# TC37X register map
File version: 1.0.0
CPU: CM4 r0p1, little endian, MPU, FPU, VTOR, 3 interrupt priority bits
Registers are 16-bit, read-write, reset 0x0 unless marked. A register's access mark holds for its fields unless they carry their own. Offsets are from the block's base; [hi:lo] are bit positions; {n}, {i} and the like mark numbered series; 'fields as' and 'values as' point back to an identical list.

## DMU — ce_dmu
Base 0xF8040000
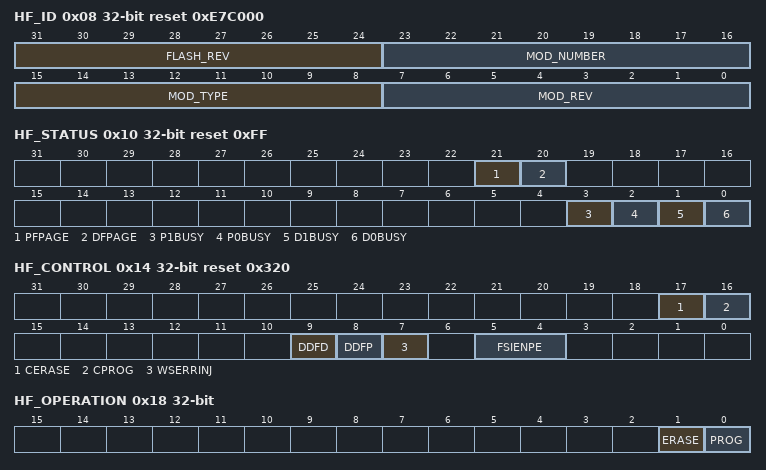
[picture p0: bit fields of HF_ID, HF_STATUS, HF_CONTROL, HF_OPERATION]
0x08 HF_ID 32-bit ro reset 0xE7C000 (reset mask 0xFFFF00) — Module Identification Register
  [31:24] FLASH_REV — Flash Revision - FLASH_REV
  [23:16] MOD_NUMBER — Module Number Value - MOD_NUMBER
  [15:8] MOD_TYPE — Module Type - MOD_TYPE
  [7:0] MOD_REV — Module Revision Number - MOD_REV
0x10 HF_STATUS 32-bit ro reset 0xFF — Flash Status Register
  [21] PFPAGE — Program Flash in Page Mode - PFPAGE
  [20] DFPAGE — Data Flash in Page Mode - DFPAGE
  [3] P1BUSY — Program Flash PF1BUSY - P1BUSY
  [2] P0BUSY — Program Flash PF0BUSY - P0BUSY
  [1] D1BUSY — Data Flash Bank 1 Busy - D1BUSY
  [0] D0BUSY — Data Flash Bank 0 Busy - D0BUSY
0x14 HF_CONTROL 32-bit reset 0x320 — Flash Control Register
  [17] CERASE wo — Clear Erase State - CERASE
  [16] CPROG wo — Clear Programming State - CPROG
  [9] DDFD — Disable Data Fetch from DF0_EEPROM - DDFD
  [8] DDFP — Disable Read from PFLASH - DDFP
  [7] WSERRINJ — PFlash Wait State ECC error injection - WSERRINJ
  [5:4] FSIENPE — Enable Program/Erase - FSIENPE
0x18 HF_OPERATION 32-bit ro — Flash Operation Register
  [1] ERASE — Erase State - ERASE
  [0] PROG — Programming State - PROG
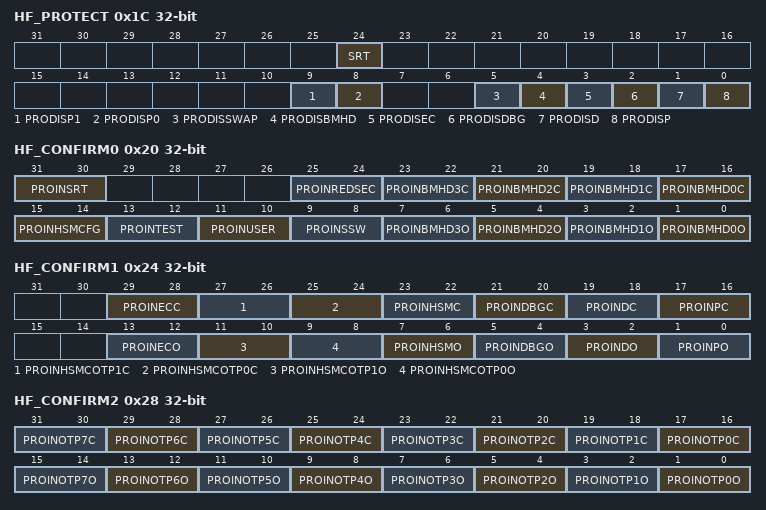
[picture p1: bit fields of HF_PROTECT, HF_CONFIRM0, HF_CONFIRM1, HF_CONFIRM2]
0x1C HF_PROTECT 32-bit ro — Flash Protection Status Register
  [24] SRT — Secure Retest Password Protection Disabled - SRT
  [9] PRODISP1 — Program Flash Protection Disable PRODISP1
  [8] PRODISP0 — Program Flash Protection Disable PRODISP0
  [5] PRODISSWAP — UCB_SWAP protection Disabled - PRODISSWAP
  [4] PRODISBMHD — BMHD Protection Disabled - PRODISBMHD
  [3] PRODISEC — Erase Counter Priority Protection Disabled - PRODISEC
  [2] PRODISDBG — Debug Interface Password Protection Disabled - PRODISDBG
  [1] PRODISD — DFLASH Protection Disabled - PRODISD
  [0] PRODISP — PFLASH Protection Disabled - PRODISP
0x20 HF_CONFIRM0 32-bit ro — Flash Confirm Status Register 0
  [31:30] PROINSRT — UCB_RETEST Confirmation - PROINSRT
  [25:24] PROINREDSEC — UCB_REDSEC Confirmation - PROINREDSEC
  [2n+17:2n+16] PROINBMHD{n}C (n=0..3) — UCB_BMHD{n}_COPY Confirmation - PROINBMHD{n}C
  [15:14] PROINHSMCFG — UCB_HSMCFG Confirmation - PROINHSMCFG
  [13:12] PROINTEST — UCB_TEST Confirmation - PROINTEST
  [11:10] PROINUSER — UCB_USER Confirmation - PROINUSER
  [9:8] PROINSSW — UCB_SSW Confirmation - PROINSSW
  [2n+1:2n] PROINBMHD{n}O (n=0..3) — UCB_BMHD{n}_ORIG Confirmation - PROINBMHD{n}O
0x24 HF_CONFIRM1 32-bit ro — Flash Confirm Status Register 1
  [29:28] PROINECC — UCB_ECPRIO_COPY Confirmation - PROINECC
  [27:26] PROINHSMCOTP1C — UCB_HSMCOTP1_COPY Protection - PROINHSMCOTP1C
  [25:24] PROINHSMCOTP0C — UCB_HSMCOTP0_COPY Protection - PROINHSMCOTP0C
  [23:22] PROINHSMC — UCB_HSM_COPY Confirmation - PROINHSMC
  [21:20] PROINDBGC — UCB_DBG_COPY Interface Confirmation - PROINDBGC
  [19:18] PROINDC — UCB_DFLASH_COPY Confirmation - PROINDC
  [17:16] PROINPC — UCB_PFLASH_COPY Confirmation - PROINPC
  [13:12] PROINECO — UCB_ECPRIO_ORIG Confirmation - PROINECO
  [11:10] PROINHSMCOTP1O — UCB_HSMCOTP1_ORIG Protection - PROINHSMCOTP1O
  [9:8] PROINHSMCOTP0O — UCB_HSMCOTP0_ORIG Protection - PROINHSMCOTP0O
  [7:6] PROINHSMO — UCB_HSM_ORIG Confirmation - PROINHSMO
  [5:4] PROINDBGO — UCB_DBG_ORIG Confirmation - PROINDBGO
  [3:2] PROINDO — UCB_DFLASH_ORIG Confirmation - PROINDO
  [1:0] PROINPO — UCB_PFLASH_ORIG Confirmation - PROINPO
0x28 HF_CONFIRM2 32-bit ro — Flash Confirm Status Register 2
  [2n+17:2n+16] PROINOTP{n}C (n=0..7) — UCB_OTP{n}_COPY Confirmation - PROINOTP{n}C
  [2n+1:2n] PROINOTP{n}O (n=0..7) — UCB_OTP{n}_ORIG Confirmation - PROINOTP{n}O
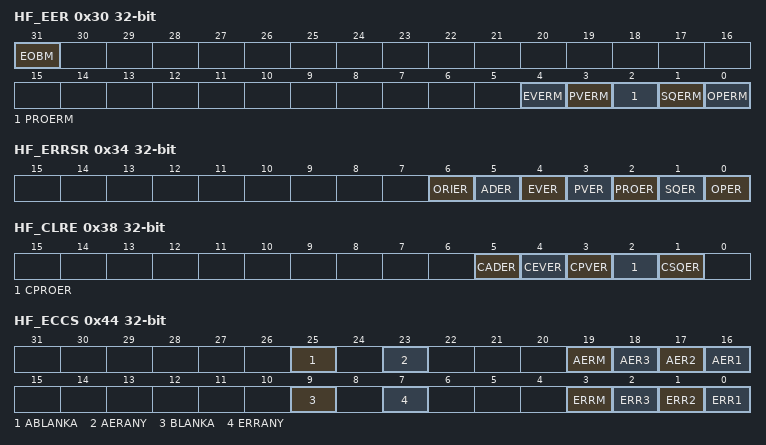
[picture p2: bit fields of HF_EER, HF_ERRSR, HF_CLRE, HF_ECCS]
0x30 HF_EER 32-bit — Enable Error Interrupt Control Register
  [31] EOBM — End of Busy Interrupt Mask - EOBM
  [4] EVERM — Erase Verify Error Interrupt Mask - EVERM
  [3] PVERM — Program Verify Error Interrupt Mask - PVERM
  [2] PROERM — Protection Error Interrupt Mask - PROERM
  [1] SQERM — Command Sequence Error Interrupt Mask - SQERM
  [0] OPERM — Operation Error Interrupt Mask - OPERM
0x34 HF_ERRSR 32-bit ro — Error Status Register
  [6] ORIER — Original Error - ORIER
  [5] ADER — SRI Bus Address ECC Error - ADER
  [4] EVER — Erase Verify Error - EVER
  [3] PVER — Program Verify Error - PVER
  [2] PROER — Protection Error - PROER
  [1] SQER — Command Sequence Error - SQER
  [0] OPER — Flash Operation Error - OPER
0x38 HF_CLRE 32-bit — Clear Error Register
  [5] CADER wo — Clear SRI Bus Address ECC Error - CADER
  [4] CEVER wo — Clear Erase Verify Error - CEVER
  [3] CPVER wo — Clear Program Verify Error - CPVER
  [2] CPROER wo — Clear Protection Error - CPROER
  [1] CSQER wo — Clear Command Sequence Error - CSQER
0x40 HF_ECCR 32-bit ro — DF0 ECC Read Register
  [21:0] RCODE — Error Correction Read Code - RCODE
0x44 HF_ECCS 32-bit ro — DF0 ECC Status Register
  [25] ABLANKA — Accumulated Blank Analog - ABLANKA
  [23] AERANY — Accumulated Any Read Access ECC Error - AERANY
  [19] AERM — Accumulated Multi-bit ECC Errors - AERM
  [18] AER3 — Accumulated Triple Bit ECC Errors - AER3
  [17] AER2 — Accumulated Double Bit ECC Errors - AER2
  [16] AER1 — Accumulated Single Bit ECC Errors - AER1
  [9] BLANKA — Read Access Blank Analog - BLANKA
  [7] ERRANY — Any Read Access ECC Error - ERRANY
  [3] ERRM — Read Access Multi-bit ECC Error - ERRM
  [2] ERR3 — Read Access Triple Bit ECC Error - ERR3
  [1] ERR2 — Read Access Double Bit ECC Error - ERR2
  [0] ERR1 — Read Access Single Bit ECC Error - ERR1
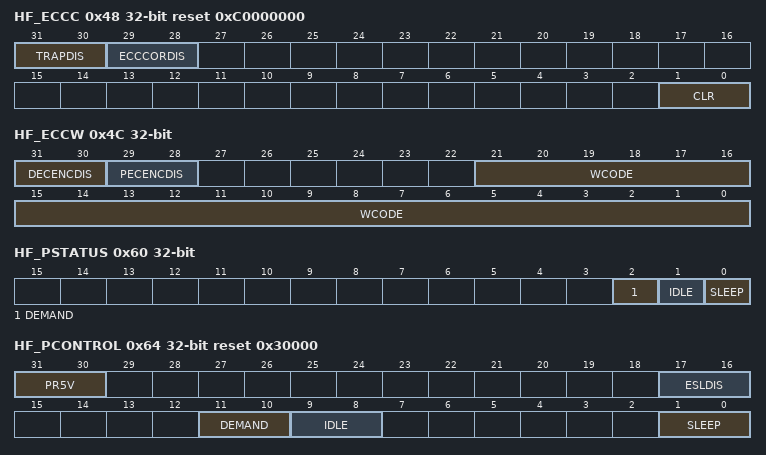
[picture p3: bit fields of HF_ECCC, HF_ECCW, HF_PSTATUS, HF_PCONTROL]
0x48 HF_ECCC 32-bit reset 0xC0000000 — DF0 ECC Control Register
  [31:30] TRAPDIS — Host Command Interface Uncorrectable ECC Bit Error Trap Disable - TRAPDIS
  [29:28] ECCCORDIS — Host Command Interface ECC Correction Disable - ECCCORDIS
  [1:0] CLR wo — Clear ECC status bits - CLR
0x4C HF_ECCW 32-bit — DF0 ECC Write Register
  [31:30] DECENCDIS — DFLASH ECC Encoding Disable - DECENCDIS
  [29:28] PECENCDIS — PFLASH ECC Encoding Disable - PECENCDIS
  [21:0] WCODE — Error Correction Write Code - WCODE
0x50 HF_CCONTROL 32-bit — Cranking Control Register
  [1:0] CRANKING — Cranking Mode Control - CRANKING
0x60 HF_PSTATUS 32-bit ro — Power Status Register
  [2] DEMAND — Demand - DEMAND
  [1] IDLE — Dynamic Idle - IDLE
  [0] SLEEP — Sleep Mode - SLEEP
0x64 HF_PCONTROL 32-bit reset 0x30000 — Power Control Register
  [31:30] PR5V — Programming Supply 5V - PR5V
  [17:16] ESLDIS — External Sleep Mode Request Disable - ESLDIS
  [11:10] DEMAND wo — Demand Enable - DEMAND
  [9:8] IDLE wo — Dynamic Idle Enable - IDLE
  [1:0] SLEEP — Sleep Mode Control - SLEEP
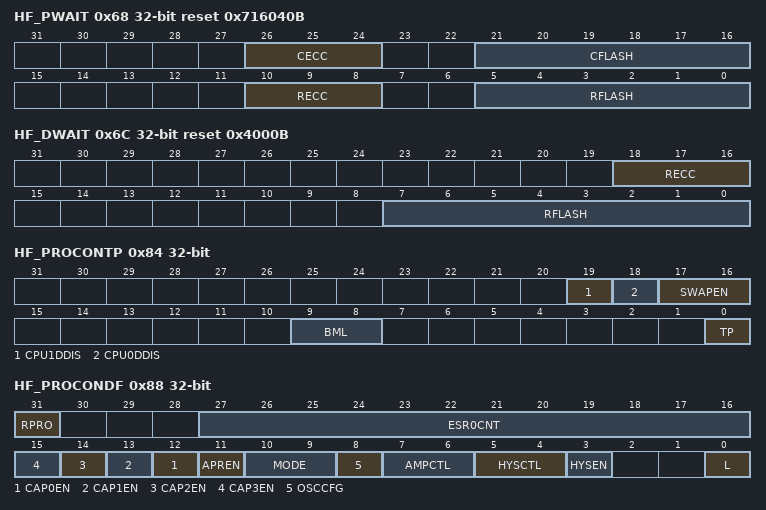
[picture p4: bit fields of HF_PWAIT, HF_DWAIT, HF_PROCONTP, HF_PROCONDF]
0x68 HF_PWAIT 32-bit reset 0x716040B — PFLASH Wait Cycle Register
  [26:24] CECC — Cranking Mode - CECC
  [21:16] CFLASH — Cranking Mode - CFLASH
  [10:8] RECC — Operation Mode - RECC
  [5:0] RFLASH — Operation Mode - RFLASH
0x6C HF_DWAIT 32-bit reset 0x4000B — DFLASH Wait Cycle Register
  [18:16] RECC — Operation Mode - RECC
  [7:0] RFLASH — Operation Mode - RFLASH
0x74 HF_PROCONUSR 32-bit ro — DF0 User Mode Control
  [1:0] MODE — DF0 User Mode Control - MODE
0x80 HF_PROCONPF 32-bit ro — PFLASH Protection Configuration
  [31] RPRO — Read Protection Configuration - RPRO
0x84 HF_PROCONTP 32-bit ro — Tuning Protection Configuration
  [19] CPU1DDIS — Disable direct LPB access
  [18] CPU0DDIS — Disable direct LPB access
  [17:16] SWAPEN — Enable SOTA mode - SWAPEN
  [9:8] BML — Boot Mode Lock - BML
  [0] TP — Tuning Protection - TP
0x88 HF_PROCONDF 32-bit ro — DFLASH Protection Configuration
  [31] RPRO — Read Protection Configuration - RPRO
  [27:16] ESR0CNT — ESR0 Prolongation Counter - ESR0CNT
  [n+12] CAP{n}EN (n=0..3) — OSC Capacitance {n} Enable (x=0-3) - CAP{n}EN
  [11] APREN — OSC Amplitude Regulation Enable - APREN
  [10:9] MODE — OSC Mode - MODE
  [8] OSCCFG — OSC Configuration by SSW - OSCCFG
  [7:6] AMPCTL — Amplitude Control
  [5:4] HYSCTL — Hysteresis Control
  [3] HYSEN — Hysteresis enable
  [0] L — DF0_EEPROM Locked for Write Protection - L
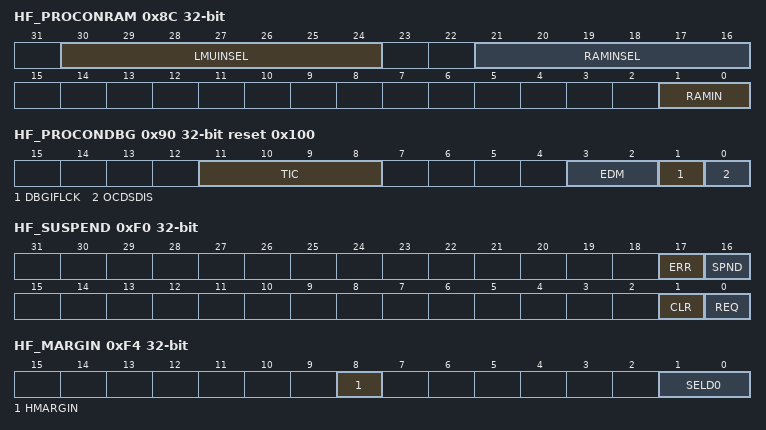
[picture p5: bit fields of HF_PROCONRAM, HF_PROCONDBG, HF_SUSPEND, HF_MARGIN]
0x8C HF_PROCONRAM 32-bit ro — RAM Configuration
  [30:24] LMUINSEL — LMU Initialization Selection - LMUINSEL
  [21:16] RAMINSEL — RAM Initialization Selection - RAMINSEL
  [1:0] RAMIN — RAM Initialization by SSW Control - RAMIN
0x90 HF_PROCONDBG 32-bit ro reset 0x100 — Debug Interface Protection Configuration
  [11:8] TIC — Tool Interface Control - TIC
  [3:2] EDM — Entered Debug Mode - EDM
  [1] DBGIFLCK — Debug Interface Locked - DBGIFLCK
  [0] OCDSDIS — OCDS Disabled - OCDSDIS
0xF0 HF_SUSPEND 32-bit — Suspend Control Register
  [17] ERR ro — Suspend Error - ERR
  [16] SPND ro — Flash Operation Suspended - SPND
  [1] CLR wo — Suspend Clear - CLR
  [0] REQ — Suspend Request - REQ
0xF4 HF_MARGIN 32-bit — Margin Control Register
  [8] HMARGIN — Hard Margin Selection - HMARGIN
  [1:0] SELD0 — DF0 Margin Read Selection - SELD0
0xF8 HF_ACCEN1 32-bit ro — Access Enable Register 1
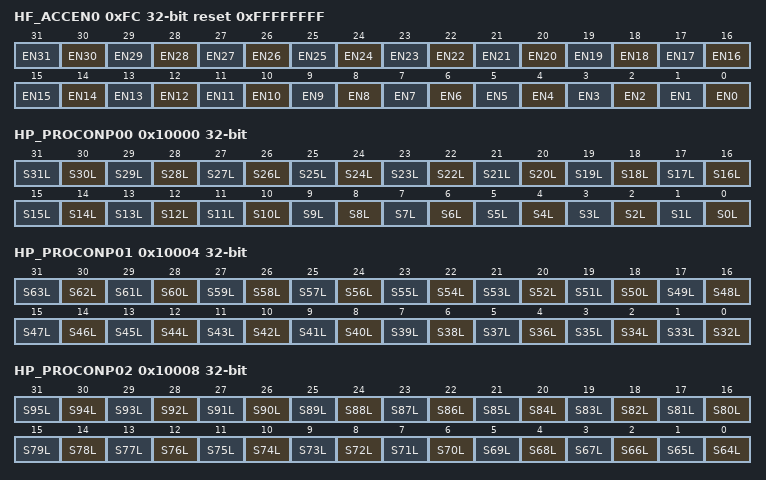
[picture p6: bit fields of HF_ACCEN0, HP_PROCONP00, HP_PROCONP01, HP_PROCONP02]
0xFC HF_ACCEN0 32-bit reset 0xFFFFFFFF — Access Enable Register 0
  [n] EN{n} (n=0..31) — Access Enable for Master TAG ID {n} - EN{n}
0x10000 HP_PROCONP00 32-bit ro — PFLASH Bank 0 Protection Configuration 0
  [n] S{n}L (n=0..31) — PFLASH p Sector {n} Locked for Write Protection - S{n}L
0x10004 HP_PROCONP01 32-bit ro — PFLASH Bank 0 Protection Configuration 1
  [n-32] S{n}L (n=32..63) — PFLASH p Sector {n} Locked for Write Protection - S{n}L
0x10008 HP_PROCONP02 32-bit ro — PFLASH Bank 0 Protection Configuration 2
  [n-64] S{n}L (n=64..95) — PFLASH p Sector {n} Locked for Write Protection - S{n}L
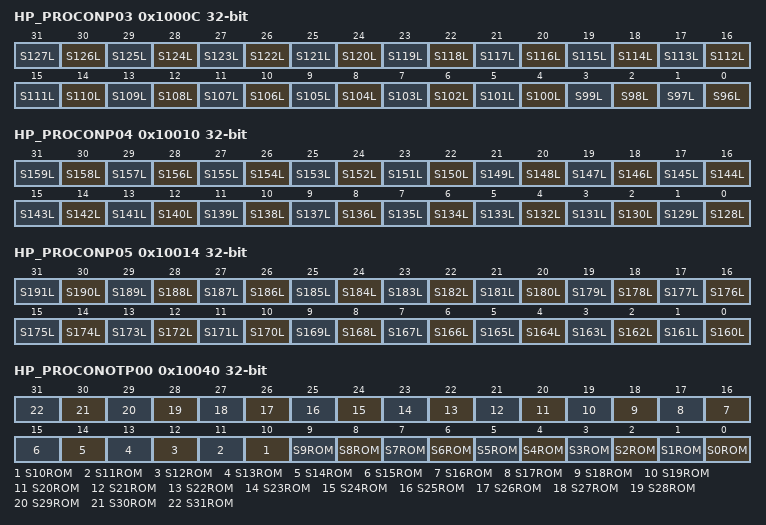
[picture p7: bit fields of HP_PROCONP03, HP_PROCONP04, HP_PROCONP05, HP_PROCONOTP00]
0x1000C HP_PROCONP03 32-bit ro — PFLASH Bank 0 Protection Configuration 3
  [n-96] S{n}L (n=96..127) — PFLASH p Sector {n} Locked for Write Protection - S{n}L
0x10010 HP_PROCONP04 32-bit ro — PFLASH Bank 0 Protection Configuration 4
  [n-128] S{n}L (n=128..159) — PFLASH p Sector {n} Locked for Write Protection - S{n}L
0x10014 HP_PROCONP05 32-bit ro — PFLASH Bank 0 Protection Configuration 5
  [n-160] S{n}L (n=160..191) — PFLASH p Sector {n} Locked for Write Protection - S{n}L
0x10040 HP_PROCONOTP00 32-bit ro — PFLASH Bank 0 OTP Protection Configuration 0
  [n] S{n}ROM (n=0..31) — PFLASH p Sector {n} Locked for Forever - S{n}ROM
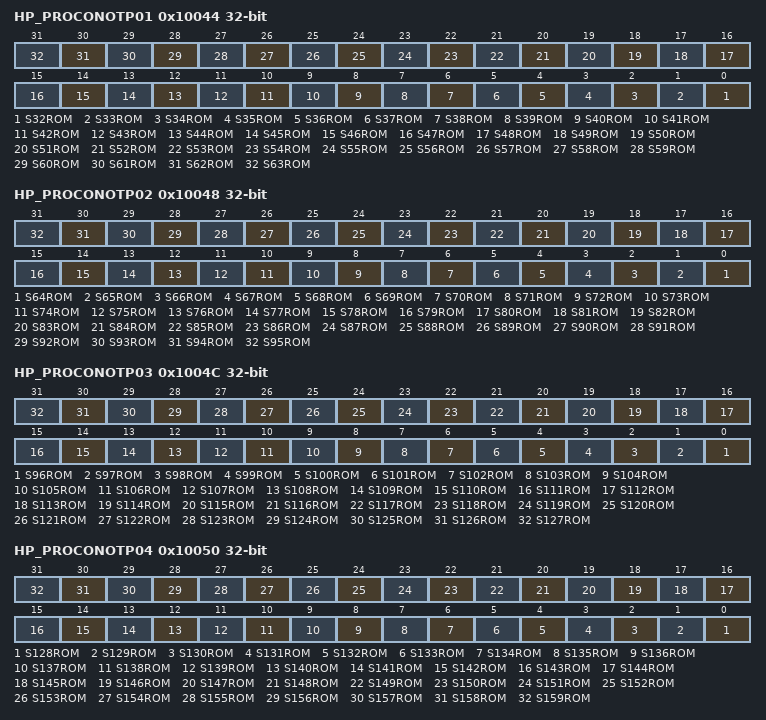
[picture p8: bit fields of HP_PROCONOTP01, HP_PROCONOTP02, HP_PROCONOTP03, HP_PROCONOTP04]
0x10044 HP_PROCONOTP01 32-bit ro — PFLASH Bank 0 OTP Protection Configuration 1
  [n-32] S{n}ROM (n=32..63) — PFLASH p Sector {n} Locked for Forever - S{n}ROM
0x10048 HP_PROCONOTP02 32-bit ro — PFLASH Bank 0 OTP Protection Configuration 2
  [n-64] S{n}ROM (n=64..95) — PFLASH p Sector {n} Locked for Forever - S{n}ROM
0x1004C HP_PROCONOTP03 32-bit ro — PFLASH Bank 0 OTP Protection Configuration 3
  [n-96] S{n}ROM (n=96..127) — PFLASH p Sector {n} Locked for Forever - S{n}ROM
0x10050 HP_PROCONOTP04 32-bit ro — PFLASH Bank 0 OTP Protection Configuration 4
  [n-128] S{n}ROM (n=128..159) — PFLASH p Sector {n} Locked for Forever - S{n}ROM
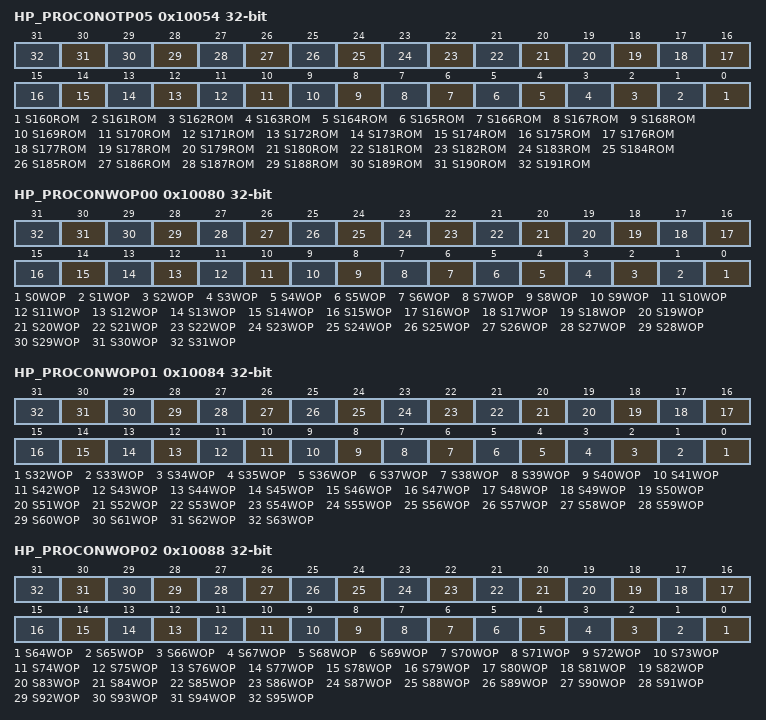
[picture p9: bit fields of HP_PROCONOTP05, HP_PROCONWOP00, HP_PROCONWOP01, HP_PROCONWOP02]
0x10054 HP_PROCONOTP05 32-bit ro — PFLASH Bank 0 OTP Protection Configuration 5
  [n-160] S{n}ROM (n=160..191) — PFLASH p Sector {n} Locked for Forever - S{n}ROM
0x10080 HP_PROCONWOP00 32-bit ro — PFLASH Bank 0 WOP Configuration 0
  [n] S{n}WOP (n=0..31) — PFLASH p Sector {n} Configured for Write-Once Protection - S{n}WOP
0x10084 HP_PROCONWOP01 32-bit ro — PFLASH Bank 0 WOP Configuration 1
  [n-32] S{n}WOP (n=32..63) — PFLASH p Sector {n} Configured for Write-Once Protection - S{n}WOP
0x10088 HP_PROCONWOP02 32-bit ro — PFLASH Bank 0 WOP Configuration 2
  [n-64] S{n}WOP (n=64..95) — PFLASH p Sector {n} Configured for Write-Once Protection - S{n}WOP
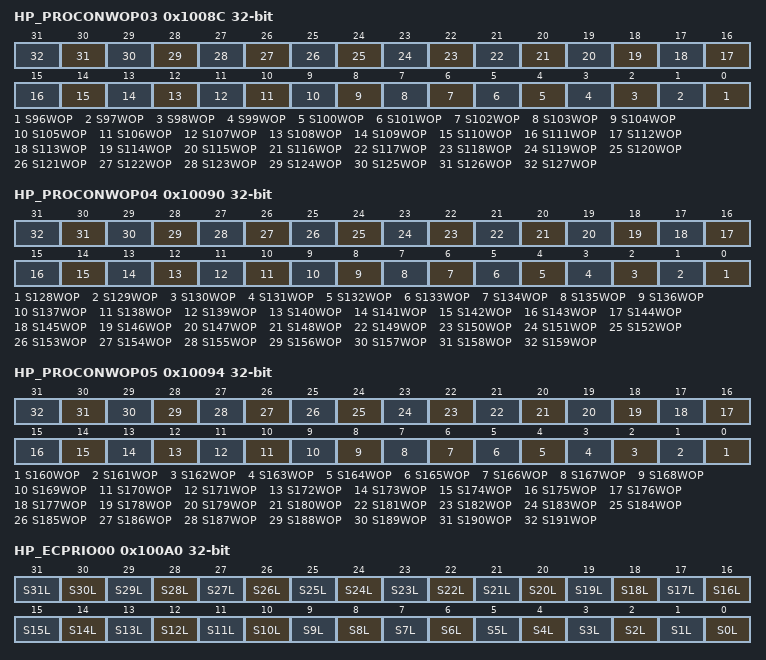
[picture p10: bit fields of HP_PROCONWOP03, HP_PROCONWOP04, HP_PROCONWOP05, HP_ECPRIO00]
0x1008C HP_PROCONWOP03 32-bit ro — PFLASH Bank 0 WOP Configuration 3
  [n-96] S{n}WOP (n=96..127) — PFLASH p Sector {n} Configured for Write-Once Protection - S{n}WOP
0x10090 HP_PROCONWOP04 32-bit ro — PFLASH Bank 0 WOP Configuration 4
  [n-128] S{n}WOP (n=128..159) — PFLASH p Sector {n} Configured for Write-Once Protection - S{n}WOP
0x10094 HP_PROCONWOP05 32-bit ro — PFLASH Bank 0 WOP Configuration 5
  [n-160] S{n}WOP (n=160..191) — PFLASH p Sector {n} Configured for Write-Once Protection - S{n}WOP
0x100A0 HP_ECPRIO00 32-bit ro — PFLASH Bank 0 Erase Counter Priority configuration 0
  [n] S{n}L (n=0..31) — PFLASH p Sector {n} Erase Counter priority - S{n}L
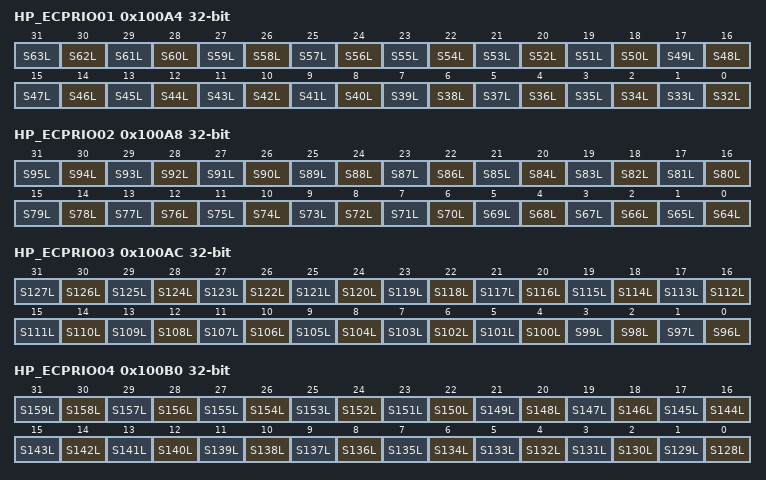
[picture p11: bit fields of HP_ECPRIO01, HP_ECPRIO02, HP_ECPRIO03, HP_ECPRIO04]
0x100A4 HP_ECPRIO01 32-bit ro — PFLASH Bank 0 Erase Counter Priority Configuration 1
  [n-32] S{n}L (n=32..63) — PFLASH p Sector {n} Erase Counter priority - S{n}L
0x100A8 HP_ECPRIO02 32-bit ro — PFLASH Bank 0 Erase Counter Priority Configuration 2
  [n-64] S{n}L (n=64..95) — PFLASH p Sector {n} Erase Counter priority - S{n}L
0x100AC HP_ECPRIO03 32-bit ro — PFLASH Bank 0 Erase Counter Priority Configuration 3
  [n-96] S{n}L (n=96..127) — PFLASH p Sector {n} Erase Counter priority - S{n}L
0x100B0 HP_ECPRIO04 32-bit ro — PFLASH Bank 0 Erase Counter Priority Configuration 4
  [n-128] S{n}L (n=128..159) — PFLASH p Sector {n} Erase Counter priority - S{n}L
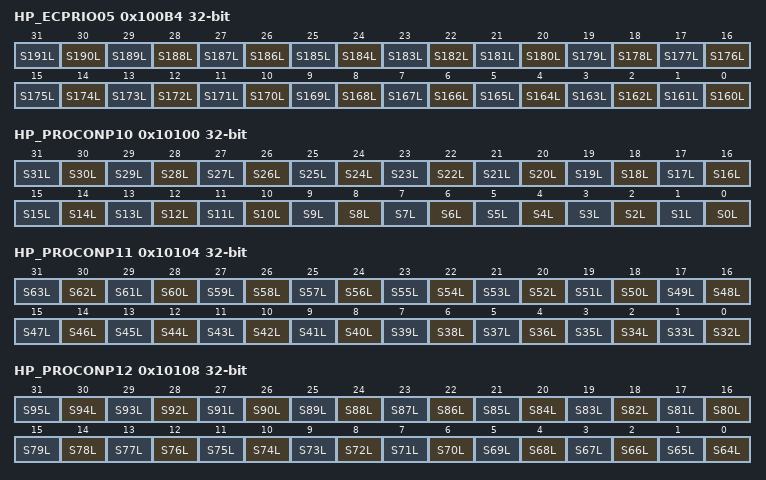
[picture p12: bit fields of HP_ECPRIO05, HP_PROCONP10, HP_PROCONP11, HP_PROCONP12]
0x100B4 HP_ECPRIO05 32-bit ro — PFLASH Bank 0 Erase Counter Priority Configuration 5
  [n-160] S{n}L (n=160..191) — PFLASH p Sector {n} Erase Counter priority - S{n}L
0x10100 HP_PROCONP10 32-bit ro — PFLASH Bank 1 Protection Configuration 0
  fields as HP_PROCONP00
0x10104 HP_PROCONP11 32-bit ro — PFLASH Bank 1 Protection Configuration 1
  fields as HP_PROCONP01
0x10108 HP_PROCONP12 32-bit ro — PFLASH Bank 1 Protection Configuration 2
  fields as HP_PROCONP02
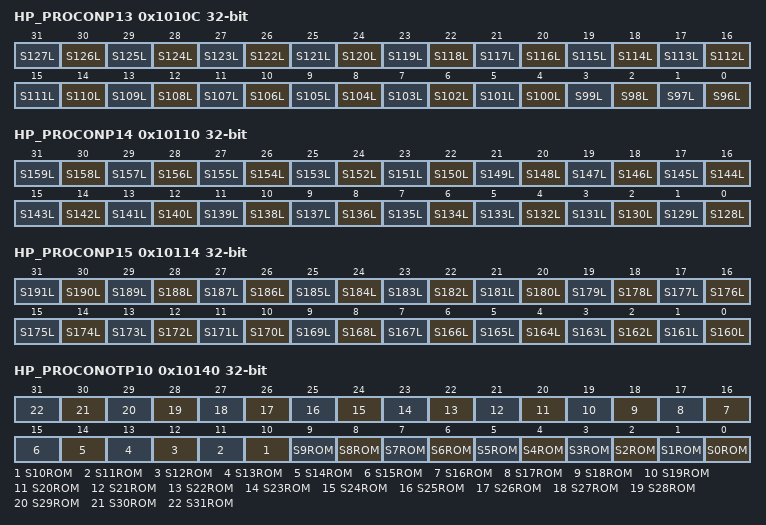
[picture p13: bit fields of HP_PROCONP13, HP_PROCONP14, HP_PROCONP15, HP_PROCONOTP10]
0x1010C HP_PROCONP13 32-bit ro — PFLASH Bank 1 Protection Configuration 3
  fields as HP_PROCONP03
0x10110 HP_PROCONP14 32-bit ro — PFLASH Bank 1 Protection Configuration 4
  fields as HP_PROCONP04
0x10114 HP_PROCONP15 32-bit ro — PFLASH Bank 1 Protection Configuration 5
  fields as HP_PROCONP05
0x10140 HP_PROCONOTP10 32-bit ro — PFLASH Bank 1 OTP Protection Configuration 0
  fields as HP_PROCONOTP00
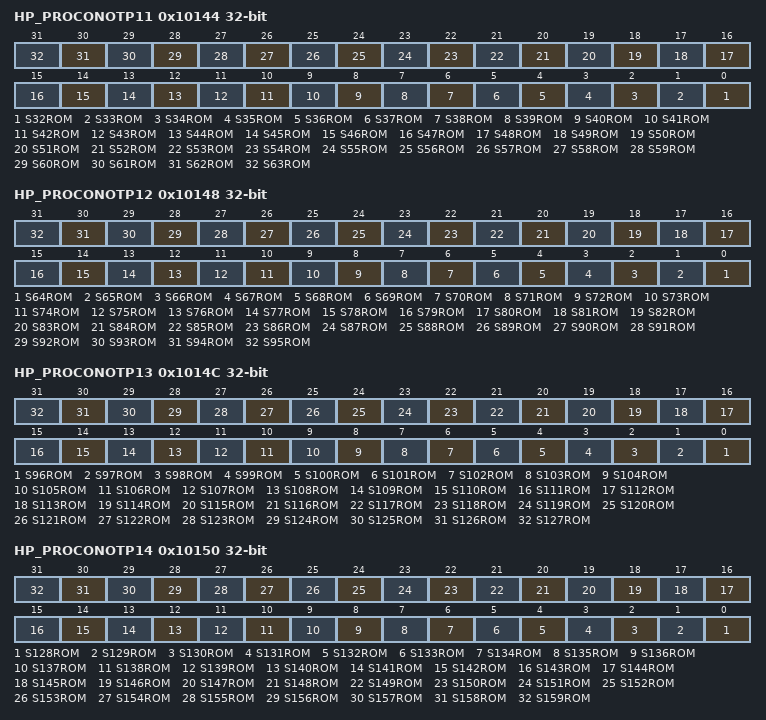
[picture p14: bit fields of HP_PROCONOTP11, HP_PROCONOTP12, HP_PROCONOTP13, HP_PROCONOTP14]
0x10144 HP_PROCONOTP11 32-bit ro — PFLASH Bank 1 OTP Protection Configuration 1
  fields as HP_PROCONOTP01
0x10148 HP_PROCONOTP12 32-bit ro — PFLASH Bank 1 OTP Protection Configuration 2
  fields as HP_PROCONOTP02
0x1014C HP_PROCONOTP13 32-bit ro — PFLASH Bank 1 OTP Protection Configuration 3
  fields as HP_PROCONOTP03
0x10150 HP_PROCONOTP14 32-bit ro — PFLASH Bank 1 OTP Protection Configuration 4
  fields as HP_PROCONOTP04
0x10154 HP_PROCONOTP15 32-bit ro — PFLASH Bank 1 OTP Protection Configuration 5
  fields as HP_PROCONOTP05
0x10180 HP_PROCONWOP10 32-bit ro — PFLASH Bank 1 WOP Configuration 0
  fields as HP_PROCONWOP00
0x10184 HP_PROCONWOP11 32-bit ro — PFLASH Bank 1 WOP Configuration 1
  fields as HP_PROCONWOP01
0x10188 HP_PROCONWOP12 32-bit ro — PFLASH Bank 1 WOP Configuration 2
  fields as HP_PROCONWOP02
0x1018C HP_PROCONWOP13 32-bit ro — PFLASH Bank 1 WOP Configuration 3
  fields as HP_PROCONWOP03
0x10190 HP_PROCONWOP14 32-bit ro — PFLASH Bank 1 WOP Configuration 4
  fields as HP_PROCONWOP04
0x10194 HP_PROCONWOP15 32-bit ro — PFLASH Bank 1 WOP Configuration 5
  fields as HP_PROCONWOP05
0x101A0 HP_ECPRIO10 32-bit ro — PFLASH Bank 1 Erase Counter Priority configuration 0
  fields as HP_ECPRIO00
0x101A4 HP_ECPRIO11 32-bit ro — PFLASH Bank 1 Erase Counter Priority Configuration 1
  fields as HP_ECPRIO01
0x101A8 HP_ECPRIO12 32-bit ro — PFLASH Bank 1 Erase Counter Priority Configuration 2
  fields as HP_ECPRIO02
0x101AC HP_ECPRIO13 32-bit ro — PFLASH Bank 1 Erase Counter Priority Configuration 3
  fields as HP_ECPRIO03
0x101B0 HP_ECPRIO14 32-bit ro — PFLASH Bank 1 Erase Counter Priority Configuration 4
  fields as HP_ECPRIO04
0x101B4 HP_ECPRIO15 32-bit ro — PFLASH Bank 1 Erase Counter Priority Configuration 5
  fields as HP_ECPRIO05
0x20010 SF_STATUS 32-bit ro reset 0x2 — HSM Flash Status Register
  [20] DFPAGE — Data Flash in Page Mode - DFPAGE
  [1] D1BUSY — Data Flash Bank 1 Busy - D1BUSY
0x20014 SF_CONTROL 32-bit reset 0x1 — HSM Flash Configuration Register
  [17] CERASE wo — Clear Erase State - CERASE
  [16] CPROG wo — Clear Programming State - CPROG
  [1:0] LCKHSMUCB — Lock Access to UCB_HSMCFG - LCKHSMUCB
0x20018 SF_OPERATION 32-bit ro — HSM Flash Operation Register
  fields as HF_OPERATION
0x20030 SF_EER 32-bit — HSM Enable Error Interrupt Control Register
  [31] EOBM — End of Busy Interrupt Mask - EOBM
  [4] EVERM — Erase Verify Error Interrupt Mask - EVERM
  [3] PVERM — Program Verify Error Interrupt Mask - PVERM
  [1] SQERM — Command Sequence Error Interrupt Mask - SQERM
  [0] OPERM — Operation Error Interrupt Mask - OPERM
0x20034 SF_ERRSR 32-bit ro — HSM Error Status Register
  [4] EVER — Erase Verify Error - EVER
  [3] PVER — Program Verify Error - PVER
  [1] SQER — Command Sequence Error - SQER
  [0] OPER — Flash Operation Error - OPER
0x20038 SF_CLRE 32-bit — HSM Clear Error Register
  [4] CEVER wo — Clear Erase Verify Error - CEVER
  [3] CPVER wo — Clear Program Verify Error - CPVER
  [1] CSQER wo — Clear Command Sequence Error - CSQER
0x20040 SF_ECCR 32-bit ro — HSM DF1 ECC Read Register
  [21:0] RCODE — Error Correction Read Code - RCODE
0x20044 SF_ECCS 32-bit ro — HSM DF1 ECC Status Register
  fields as HF_ECCS
0x20048 SF_ECCC 32-bit reset 0xC0000000 — HSM DF1 ECC Control Register
  [31:30] TRAPDIS — HSM Command Interface Uncorrectable ECC Bit Error Trap Disable - TRAPDIS
  [29:28] ECCCORDIS — HSM Command Interface ECC Correction Disable - ECCCORDIS
  [1:0] CLR wo — Clear ECC status bits - CLR
0x2004C SF_ECCW 32-bit — HSM DF1 ECC Write Register
  [31:30] ECCENCDIS — ECC Encoding Disable - ECCENCDIS
  [21:0] WCODE — Error Correction Write Code - WCODE
0x20074 SF_PROCONUSR 32-bit ro — HSM DF1 User Mode Control
  [1:0] MODE — DF1 User Mode Control - MODE
0x200E8 SF_SUSPEND 32-bit — HSM Suspend Control Register
  fields as HF_SUSPEND
0x200EC SF_MARGIN 32-bit — HSM DF1 Margin Control Register
  [8] HMARGIN — Hard Margin Selection - HMARGIN
  [1:0] SELD1 — DF1 Margin Read Selection - SELD1
0x30000 SP_PROCONHSMCFG 32-bit ro — HSM Protection Configuration
  [13] BLKFLAN — Block Flash Analysis - BLKFLAN
  [12:11] DESTDBG — Destructive Debug Entry - DESTDBG
  [10:9] HSMENRES — Enable HSM Triggering Resets - HSMENRES
  [8:7] HSMENPINS — Enable HSM Forcing of Pins HSM1/2 - HSMENPINS
  [5:4] HSMRAMKEEP — HSM RAM Clear - HSMRAMKEEP
  [2] HSMDX — HSM Data Sectors Exclusive - HSMDX
  [1] SSWWAIT — SSW Wait - SSWWAIT
  [0] HSMBOOTEN — HSM Boot Enable - HSMBOOTEN
0x30004 SP_PROCONHSMCBS 32-bit ro — HSM Code Boot Sector
  [8n+5:8n] BOOTSEL{n} (n=0..3) — Boot Sector Selection - BOOTSEL{n}
0x30008 SP_PROCONHSMCX0 32-bit ro — HSM Code Exclusive Protection Configuration
  [n] HSM{n}X (n=0..31) — PFLASH Sector {n} HSM Code Exclusive - HSM{n}X
0x3000C SP_PROCONHSMCX1 32-bit ro — HSM Code Exclusive Protection Configuration
  [n-32] HSM{n}X (n=32..39) — PFLASH Sector {n} HSM Code Exclusive - HSM{n}X
0x30010 SP_PROCONHSMCOTP0 32-bit ro — HSM Code OTP Protection Configuration
  [n] HSM{n}ROM (n=0..31) — PFLASH Sector {n} HSM Code Locked Forever - HSM{n}ROM
0x30014 SP_PROCONHSMCOTP1 32-bit ro — HSM Code OTP Protection Configuration
  [n-32] HSM{n}ROM (n=32..39) — PFLASH Sector {n} HSM Code Locked Forever - HSM{n}ROM
0x30040 SP_PROCONHSM 32-bit ro — HSM Interface Protection Configuration
  [6] HSMTRTYPE — HSM Type of Trace - HSMTRTYPE
  [5:4] HSMTRDIS — HSM Trace Disable - HSMTRDIS
  [3] HSMTSTDIS — HSM Test Disable - HSMTSTDIS
  [2] TSTIFLCK — Test Interface Locked - TSTIFLCK
  [1] DBGIFLCK — Debug Interface Locked - DBGIFLCK
  [0] HSMDBGDIS — HSM Debug Disable - HSMDBGDIS
